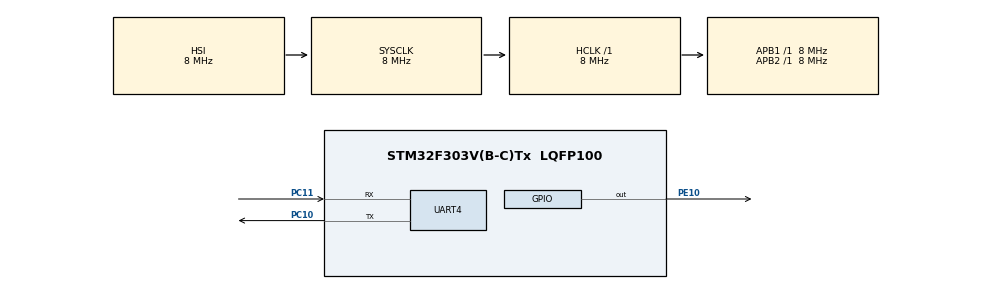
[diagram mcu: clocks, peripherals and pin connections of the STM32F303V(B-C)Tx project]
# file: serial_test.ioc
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Mcu.Family=STM32F3
Mcu.Name=STM32F303V(B-C)Tx
Mcu.Package=LQFP100
NVIC.PriorityGroup=NVIC_PRIORITYGROUP_4
NVIC.UART4_IRQn=true\:0\:0\:false\:true\:true\:1\:true\:true\:true
PC10.Mode=Asynchronous
PC10.Signal=UART4_TX
PC11.Mode=Asynchronous
PC11.Signal=UART4_RX
PE10.Signal=GPIO_Output
ProjectManager.HeapSize=0x200
ProjectManager.StackSize=0x400
ProjectManager.TargetToolchain=STM32CubeIDE
RCC.AHBFreq_Value=8000000
RCC.APB1Freq_Value=8000000
RCC.APB2Freq_Value=8000000
RCC.CortexFreq_Value=8000000
RCC.HSE_VALUE=8000000
RCC.HSI_VALUE=8000000
RCC.LSE_VALUE=32768
RCC.SYSCLKFreq_VALUE=8000000
board=custom

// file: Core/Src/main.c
/* USER CODE BEGIN Header */
/**
  ******************************************************************************
  * @file           : main.c
  * @brief          : Main program body
  ******************************************************************************
  * @attention
  *
  * Copyright (c) 2025 STMicroelectronics.
  * All rights reserved.
  *
  * This software is licensed under terms that can be found in the LICENSE file
  * in the root directory of this software component.
  * If no LICENSE file comes with this software, it is provided AS-IS.
  *
  ******************************************************************************
  */
/* USER CODE END Header */
#include "main.h"

UART_HandleTypeDef huart4;

/* USER CODE BEGIN PV */
uint8_t rxBuffer[100];
uint8_t txBuffer[] = "HI";

/* USER CODE END PV */

void SystemClock_Config(void);
static void MX_GPIO_Init(void);
static void MX_UART4_Init(void);
static void MX_NVIC_Init(void);

int main(void)
{

  /* MCU Configuration--------------------------------------------------------*/

  /* Reset of all peripherals, Initializes the Flash interface and the Systick. */
  HAL_Init();

  /* Configure the system clock */
  SystemClock_Config();

  /* Initialize all configured peripherals */
  MX_GPIO_Init();
  MX_UART4_Init();

  /* Initialize interrupts */
  MX_NVIC_Init();
  /* USER CODE BEGIN 2 */
  HAL_UART_Receive_IT(&huart4, rxBuffer, sizeof(rxBuffer));

  /* USER CODE END 2 */

  /* Infinite loop */
  while (1)
  {

    /* USER CODE BEGIN 3 */
	  HAL_GPIO_WritePin(GPIOE, GPIO_PIN_10, GPIO_PIN_RESET);
	  HAL_UART_Transmit(&huart4, txBuffer,strlen((char *)txBuffer), HAL_MAX_DELAY);
	  HAL_Delay(1000);
	  HAL_GPIO_WritePin(GPIOE, GPIO_PIN_10, GPIO_PIN_SET);
	  HAL_Delay(1000);
  }
  /* USER CODE END 3 */
}

void SystemClock_Config(void)
{
  RCC_OscInitTypeDef RCC_OscInitStruct = {0};
  RCC_ClkInitTypeDef RCC_ClkInitStruct = {0};
  RCC_PeriphCLKInitTypeDef PeriphClkInit = {0};

  /** Initializes the RCC Oscillators according to the specified parameters
  * in the RCC_OscInitTypeDef structure.
  */
  RCC_OscInitStruct.OscillatorType = RCC_OSCILLATORTYPE_HSI;
  RCC_OscInitStruct.HSIState = RCC_HSI_ON;
  RCC_OscInitStruct.HSICalibrationValue = RCC_HSICALIBRATION_DEFAULT;
  RCC_OscInitStruct.PLL.PLLState = RCC_PLL_NONE;
  if (HAL_RCC_OscConfig(&RCC_OscInitStruct) != HAL_OK)
  {
    Error_Handler();
  }

  /** Initializes the CPU, AHB and APB buses clocks
  */
  RCC_ClkInitStruct.ClockType = RCC_CLOCKTYPE_HCLK|RCC_CLOCKTYPE_SYSCLK
                              |RCC_CLOCKTYPE_PCLK1|RCC_CLOCKTYPE_PCLK2;
  RCC_ClkInitStruct.SYSCLKSource = RCC_SYSCLKSOURCE_HSI;
  RCC_ClkInitStruct.AHBCLKDivider = RCC_SYSCLK_DIV1;
  RCC_ClkInitStruct.APB1CLKDivider = RCC_HCLK_DIV1;
  RCC_ClkInitStruct.APB2CLKDivider = RCC_HCLK_DIV1;

  if (HAL_RCC_ClockConfig(&RCC_ClkInitStruct, FLASH_LATENCY_0) != HAL_OK)
  {
    Error_Handler();
  }
  PeriphClkInit.PeriphClockSelection = RCC_PERIPHCLK_UART4;
  PeriphClkInit.Uart4ClockSelection = RCC_UART4CLKSOURCE_PCLK1;
  if (HAL_RCCEx_PeriphCLKConfig(&PeriphClkInit) != HAL_OK)
  {
    Error_Handler();
  }
}

/**
  * @brief NVIC Configuration.
  * @retval None
  */
static void MX_NVIC_Init(void)
{
  /* UART4_IRQn interrupt configuration */
  HAL_NVIC_SetPriority(UART4_IRQn, 0, 0);
  HAL_NVIC_EnableIRQ(UART4_IRQn);
}

static void MX_UART4_Init(void)
{

  huart4.Instance = UART4;
  huart4.Init.BaudRate = 115200;
  huart4.Init.WordLength = UART_WORDLENGTH_8B;
  huart4.Init.StopBits = UART_STOPBITS_1;
  huart4.Init.Parity = UART_PARITY_NONE;
  huart4.Init.Mode = UART_MODE_TX_RX;
  huart4.Init.HwFlowCtl = UART_HWCONTROL_NONE;
  huart4.Init.OverSampling = UART_OVERSAMPLING_16;
  huart4.Init.OneBitSampling = UART_ONE_BIT_SAMPLE_DISABLE;
  huart4.AdvancedInit.AdvFeatureInit = UART_ADVFEATURE_NO_INIT;
  if (HAL_UART_Init(&huart4) != HAL_OK)
  {
    Error_Handler();
  }

}

static void MX_GPIO_Init(void)
{
  GPIO_InitTypeDef GPIO_InitStruct = {0};

  /* GPIO Ports Clock Enable */
  __HAL_RCC_GPIOE_CLK_ENABLE();
  __HAL_RCC_GPIOC_CLK_ENABLE();

  /*Configure GPIO pin Output Level */
  HAL_GPIO_WritePin(GPIOE, GPIO_PIN_10, GPIO_PIN_RESET);

  /*Configure GPIO pin : PE10 */
  GPIO_InitStruct.Pin = GPIO_PIN_10;
  GPIO_InitStruct.Mode = GPIO_MODE_OUTPUT_PP;
  GPIO_InitStruct.Pull = GPIO_NOPULL;
  GPIO_InitStruct.Speed = GPIO_SPEED_FREQ_LOW;
  HAL_GPIO_Init(GPIOE, &GPIO_InitStruct);

}

/* USER CODE BEGIN 4 */
void HAL_UART_RxCpltCallback(UART_HandleTypeDef *huart) {
	if (huart->Instance == UART4) {
		HAL_UART_Receive_IT(&huart4, rxBuffer, sizeof(rxBuffer));
	}
}
/* USER CODE END 4 */

void Error_Handler(void)
{
  __disable_irq();
  while (1)
  {
  }
}
